AUTOSAR XML (schema 4-2-2)
package /LKAS_pkg/LKAS_swc
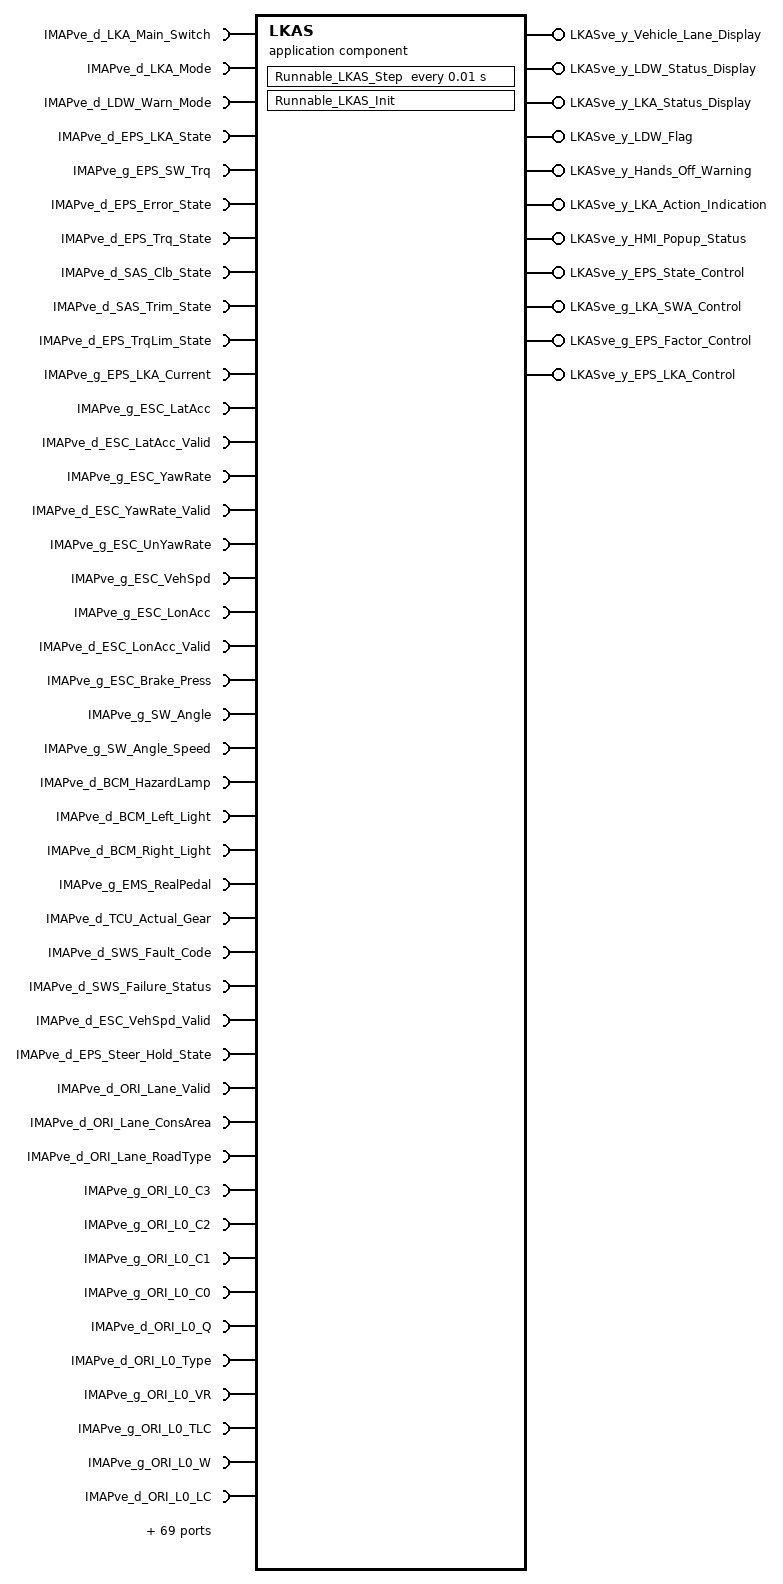
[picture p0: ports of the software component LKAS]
  application sw component type LKAS
    125 x require port:
      IMAPve_d_LKA_Main_Switch: nonqueued-receiver-com-spec{data-element=IMAPve_d_LKA_Main_Switch, init-value=0}, required-interface=IMAPve_d_LKA_Main_Switch
      IMAPve_d_LKA_Mode: nonqueued-receiver-com-spec{data-element=IMAPve_d_LKA_Mode, init-value=0}, required-interface=IMAPve_d_LKA_Mode
      IMAPve_d_LDW_Warn_Mode: nonqueued-receiver-com-spec{data-element=IMAPve_d_LDW_Warn_Mode, init-value=0}, required-interface=IMAPve_d_LDW_Warn_Mode
      IMAPve_d_EPS_LKA_State: nonqueued-receiver-com-spec{data-element=IMAPve_d_EPS_LKA_State, init-value=0}, required-interface=IMAPve_d_EPS_LKA_State
      IMAPve_g_EPS_SW_Trq: nonqueued-receiver-com-spec{data-element=IMAPve_g_EPS_SW_Trq, init-value=0}, required-interface=IMAPve_g_EPS_SW_Trq
      IMAPve_d_EPS_Error_State: nonqueued-receiver-com-spec{data-element=IMAPve_d_EPS_Error_State, init-value=0}, required-interface=IMAPve_d_EPS_Error_State
      IMAPve_d_EPS_Trq_State: nonqueued-receiver-com-spec{data-element=IMAPve_d_EPS_Trq_State, init-value=0}, required-interface=IMAPve_d_EPS_Trq_State
      IMAPve_d_SAS_Clb_State: nonqueued-receiver-com-spec{data-element=IMAPve_d_SAS_Clb_State, init-value=0}, required-interface=IMAPve_d_SAS_Clb_State
      IMAPve_d_SAS_Trim_State: nonqueued-receiver-com-spec{data-element=IMAPve_d_SAS_Trim_State, init-value=0}, required-interface=IMAPve_d_SAS_Trim_State
      IMAPve_d_EPS_TrqLim_State: nonqueued-receiver-com-spec{data-element=IMAPve_d_EPS_TrqLim_State, init-value=0}, required-interface=IMAPve_d_EPS_TrqLim_State
      IMAPve_g_EPS_LKA_Current: nonqueued-receiver-com-spec{data-element=IMAPve_g_EPS_LKA_Current, init-value=0}, required-interface=IMAPve_g_EPS_LKA_Current
      IMAPve_g_ESC_LatAcc: nonqueued-receiver-com-spec{data-element=IMAPve_g_ESC_LatAcc, init-value=0}, required-interface=IMAPve_g_ESC_LatAcc
      IMAPve_d_ESC_LatAcc_Valid: nonqueued-receiver-com-spec{data-element=IMAPve_d_ESC_LatAcc_Valid, init-value=0}, required-interface=IMAPve_d_ESC_LatAcc_Valid
      IMAPve_g_ESC_YawRate: nonqueued-receiver-com-spec{data-element=IMAPve_g_ESC_YawRate, init-value=0}, required-interface=IMAPve_g_ESC_YawRate
      IMAPve_d_ESC_YawRate_Valid: nonqueued-receiver-com-spec{data-element=IMAPve_d_ESC_YawRate_Valid, init-value=0}, required-interface=IMAPve_d_ESC_YawRate_Valid
      IMAPve_g_ESC_UnYawRate: nonqueued-receiver-com-spec{data-element=IMAPve_g_ESC_UnYawRate, init-value=0}, required-interface=IMAPve_g_ESC_UnYawRate
      IMAPve_g_ESC_VehSpd: nonqueued-receiver-com-spec{data-element=IMAPve_g_ESC_VehSpd, init-value=0}, required-interface=IMAPve_g_ESC_VehSpd
      IMAPve_g_ESC_LonAcc: nonqueued-receiver-com-spec{data-element=IMAPve_g_ESC_LonAcc, init-value=0}, required-interface=IMAPve_g_ESC_LonAcc
      IMAPve_d_ESC_LonAcc_Valid: nonqueued-receiver-com-spec{data-element=IMAPve_d_ESC_LonAcc_Valid, init-value=0}, required-interface=IMAPve_d_ESC_LonAcc_Valid
      IMAPve_g_ESC_Brake_Press: nonqueued-receiver-com-spec{data-element=IMAPve_g_ESC_Brake_Press, init-value=0}, required-interface=IMAPve_g_ESC_Brake_Press
      IMAPve_g_SW_Angle: nonqueued-receiver-com-spec{data-element=IMAPve_g_SW_Angle, init-value=0}, required-interface=IMAPve_g_SW_Angle
      IMAPve_g_SW_Angle_Speed: nonqueued-receiver-com-spec{data-element=IMAPve_g_SW_Angle_Speed, init-value=0}, required-interface=IMAPve_g_SW_Angle_Speed
      IMAPve_d_BCM_HazardLamp: nonqueued-receiver-com-spec{data-element=IMAPve_d_BCM_HazardLamp, init-value=0}, required-interface=IMAPve_d_BCM_HazardLamp
      IMAPve_d_BCM_Left_Light: nonqueued-receiver-com-spec{data-element=IMAPve_d_BCM_Left_Light, init-value=0}, required-interface=IMAPve_d_BCM_Left_Light
      IMAPve_d_BCM_Right_Light: nonqueued-receiver-com-spec{data-element=IMAPve_d_BCM_Right_Light, init-value=0}, required-interface=IMAPve_d_BCM_Right_Light
      IMAPve_g_EMS_RealPedal: nonqueued-receiver-com-spec{data-element=IMAPve_g_EMS_RealPedal, init-value=0}, required-interface=IMAPve_g_EMS_RealPedal
      IMAPve_d_TCU_Actual_Gear: nonqueued-receiver-com-spec{data-element=IMAPve_d_TCU_Actual_Gear, init-value=0}, required-interface=IMAPve_d_TCU_Actual_Gear
      IMAPve_d_SWS_Fault_Code: nonqueued-receiver-com-spec{data-element=IMAPve_d_SWS_Fault_Code, init-value=0}, required-interface=IMAPve_d_SWS_Fault_Code
      IMAPve_d_SWS_Failure_Status: nonqueued-receiver-com-spec{data-element=IMAPve_d_SWS_Failure_Status, init-value=0}, required-interface=IMAPve_d_SWS_Failure_Status
      IMAPve_d_ESC_VehSpd_Valid: nonqueued-receiver-com-spec{data-element=IMAPve_d_ESC_VehSpd_Valid, init-value=0}, required-interface=IMAPve_d_ESC_VehSpd_Valid
      IMAPve_d_EPS_Steer_Hold_State: nonqueued-receiver-com-spec{data-element=IMAPve_d_EPS_Steer_Hold_State, init-value=0}, required-interface=IMAPve_d_EPS_Steer_Hold_State
      IMAPve_d_ORI_Lane_Valid: nonqueued-receiver-com-spec{data-element=IMAPve_d_ORI_Lane_Valid, init-value=0}, required-interface=IMAPve_d_ORI_Lane_Valid
      IMAPve_d_ORI_Lane_ConsArea: nonqueued-receiver-com-spec{data-element=IMAPve_d_ORI_Lane_ConsArea, init-value=0}, required-interface=IMAPve_d_ORI_Lane_ConsArea
      IMAPve_d_ORI_Lane_RoadType: nonqueued-receiver-com-spec{data-element=IMAPve_d_ORI_Lane_RoadType, init-value=0}, required-interface=IMAPve_d_ORI_Lane_RoadType
      IMAPve_g_ORI_L0_C3: nonqueued-receiver-com-spec{data-element=IMAPve_g_ORI_L0_C3, init-value=0}, required-interface=IMAPve_g_ORI_L0_C3
      IMAPve_g_ORI_L0_C2: nonqueued-receiver-com-spec{data-element=IMAPve_g_ORI_L0_C2, init-value=0}, required-interface=IMAPve_g_ORI_L0_C2
      IMAPve_g_ORI_L0_C1: nonqueued-receiver-com-spec{data-element=IMAPve_g_ORI_L0_C1, init-value=0}, required-interface=IMAPve_g_ORI_L0_C1
      IMAPve_g_ORI_L0_C0: nonqueued-receiver-com-spec{data-element=IMAPve_g_ORI_L0_C0, init-value=0}, required-interface=IMAPve_g_ORI_L0_C0
      IMAPve_d_ORI_L0_Q: nonqueued-receiver-com-spec{data-element=IMAPve_d_ORI_L0_Q, init-value=0}, required-interface=IMAPve_d_ORI_L0_Q
      IMAPve_d_ORI_L0_Type: nonqueued-receiver-com-spec{data-element=IMAPve_d_ORI_L0_Type, init-value=0}, required-interface=IMAPve_d_ORI_L0_Type
      IMAPve_g_ORI_L0_VR: nonqueued-receiver-com-spec{data-element=IMAPve_g_ORI_L0_VR, init-value=0}, required-interface=IMAPve_g_ORI_L0_VR
      IMAPve_g_ORI_L0_TLC: nonqueued-receiver-com-spec{data-element=IMAPve_g_ORI_L0_TLC, init-value=0}, required-interface=IMAPve_g_ORI_L0_TLC
      IMAPve_g_ORI_L0_W: nonqueued-receiver-com-spec{data-element=IMAPve_g_ORI_L0_W, init-value=0}, required-interface=IMAPve_g_ORI_L0_W
      IMAPve_d_ORI_L0_LC: nonqueued-receiver-com-spec{data-element=IMAPve_d_ORI_L0_LC, init-value=0}, required-interface=IMAPve_d_ORI_L0_LC
      IMAPve_g_ORI_L1_C3: nonqueued-receiver-com-spec{data-element=IMAPve_g_ORI_L1_C3, init-value=0}, required-interface=IMAPve_g_ORI_L1_C3
      IMAPve_g_ORI_L1_C2: nonqueued-receiver-com-spec{data-element=IMAPve_g_ORI_L1_C2, init-value=0}, required-interface=IMAPve_g_ORI_L1_C2
      IMAPve_g_ORI_L1_C1: nonqueued-receiver-com-spec{data-element=IMAPve_g_ORI_L1_C1, init-value=0}, required-interface=IMAPve_g_ORI_L1_C1
      IMAPve_g_ORI_L1_C0: nonqueued-receiver-com-spec{data-element=IMAPve_g_ORI_L1_C0, init-value=0}, required-interface=IMAPve_g_ORI_L1_C0
      IMAPve_d_ORI_L1_Q: nonqueued-receiver-com-spec{data-element=IMAPve_d_ORI_L1_Q, init-value=0}, required-interface=IMAPve_d_ORI_L1_Q
      IMAPve_d_ORI_L1_Type: nonqueued-receiver-com-spec{data-element=IMAPve_d_ORI_L1_Type, init-value=0}, required-interface=IMAPve_d_ORI_L1_Type
      IMAPve_g_ORI_L1_VR: nonqueued-receiver-com-spec{data-element=IMAPve_g_ORI_L1_VR, init-value=0}, required-interface=IMAPve_g_ORI_L1_VR
      IMAPve_g_ORI_L1_TLC: nonqueued-receiver-com-spec{data-element=IMAPve_g_ORI_L1_TLC, init-value=0}, required-interface=IMAPve_g_ORI_L1_TLC
      IMAPve_g_ORI_L1_W: nonqueued-receiver-com-spec{data-element=IMAPve_g_ORI_L1_W, init-value=0}, required-interface=IMAPve_g_ORI_L1_W
      IMAPve_d_ORI_L1_LC: nonqueued-receiver-com-spec{data-element=IMAPve_d_ORI_L1_LC, init-value=0}, required-interface=IMAPve_d_ORI_L1_LC
      IMAPve_g_ORI_R0_C3: nonqueued-receiver-com-spec{data-element=IMAPve_g_ORI_R0_C3, init-value=0}, required-interface=IMAPve_g_ORI_R0_C3
      IMAPve_g_ORI_R0_C2: nonqueued-receiver-com-spec{data-element=IMAPve_g_ORI_R0_C2, init-value=0}, required-interface=IMAPve_g_ORI_R0_C2
      IMAPve_g_ORI_R0_C1: nonqueued-receiver-com-spec{data-element=IMAPve_g_ORI_R0_C1, init-value=0}, required-interface=IMAPve_g_ORI_R0_C1
      IMAPve_g_ORI_R0_C0: nonqueued-receiver-com-spec{data-element=IMAPve_g_ORI_R0_C0, init-value=0}, required-interface=IMAPve_g_ORI_R0_C0
      IMAPve_d_ORI_R0_Q: nonqueued-receiver-com-spec{data-element=IMAPve_d_ORI_R0_Q, init-value=0}, required-interface=IMAPve_d_ORI_R0_Q
      IMAPve_d_ORI_R0_LT: nonqueued-receiver-com-spec{data-element=IMAPve_d_ORI_R0_LT, init-value=0}, required-interface=IMAPve_d_ORI_R0_LT
      IMAPve_g_ORI_R0_VR: nonqueued-receiver-com-spec{data-element=IMAPve_g_ORI_R0_VR, init-value=0}, required-interface=IMAPve_g_ORI_R0_VR
      IMAPve_g_ORI_R0_TLC: nonqueued-receiver-com-spec{data-element=IMAPve_g_ORI_R0_TLC, init-value=0}, required-interface=IMAPve_g_ORI_R0_TLC
      IMAPve_g_ORI_R0_W: nonqueued-receiver-com-spec{data-element=IMAPve_g_ORI_R0_W, init-value=0}, required-interface=IMAPve_g_ORI_R0_W
      IMAPve_d_ORI_R0_LC: nonqueued-receiver-com-spec{data-element=IMAPve_d_ORI_R0_LC, init-value=0}, required-interface=IMAPve_d_ORI_R0_LC
      IMAPve_g_ORI_R1_C3: nonqueued-receiver-com-spec{data-element=IMAPve_g_ORI_R1_C3, init-value=0}, required-interface=IMAPve_g_ORI_R1_C3
      IMAPve_g_ORI_R1_C2: nonqueued-receiver-com-spec{data-element=IMAPve_g_ORI_R1_C2, init-value=0}, required-interface=IMAPve_g_ORI_R1_C2
      IMAPve_g_ORI_R1_C1: nonqueued-receiver-com-spec{data-element=IMAPve_g_ORI_R1_C1, init-value=0}, required-interface=IMAPve_g_ORI_R1_C1
      IMAPve_g_ORI_R1_C0: nonqueued-receiver-com-spec{data-element=IMAPve_g_ORI_R1_C0, init-value=0}, required-interface=IMAPve_g_ORI_R1_C0
      IMAPve_d_ORI_R1_Q: nonqueued-receiver-com-spec{data-element=IMAPve_d_ORI_R1_Q, init-value=0}, required-interface=IMAPve_d_ORI_R1_Q
      IMAPve_d_ORI_R1_LT: nonqueued-receiver-com-spec{data-element=IMAPve_d_ORI_R1_LT, init-value=0}, required-interface=IMAPve_d_ORI_R1_LT
      IMAPve_g_ORI_R1_VR: nonqueued-receiver-com-spec{data-element=IMAPve_g_ORI_R1_VR, init-value=0}, required-interface=IMAPve_g_ORI_R1_VR
      IMAPve_g_ORI_R1_TLC: nonqueued-receiver-com-spec{data-element=IMAPve_g_ORI_R1_TLC, init-value=0}, required-interface=IMAPve_g_ORI_R1_TLC
      IMAPve_g_ORI_R1_W: nonqueued-receiver-com-spec{data-element=IMAPve_g_ORI_R1_W, init-value=0}, required-interface=IMAPve_g_ORI_R1_W
      IMAPve_d_ORI_R1_LC: nonqueued-receiver-com-spec{data-element=IMAPve_d_ORI_R1_LC, init-value=0}, required-interface=IMAPve_d_ORI_R1_LC
      IMAPve_d_Sensor_Status: nonqueued-receiver-com-spec{data-element=IMAPve_d_Sensor_Status, init-value=0}, required-interface=IMAPve_d_Sensor_Status
      IMAPve_d_Fusion_Status: nonqueued-receiver-com-spec{data-element=IMAPve_d_Fusion_Status, init-value=0}, required-interface=IMAPve_d_Fusion_Status
      IMAPve_d_Lane_Valid: nonqueued-receiver-com-spec{data-element=IMAPve_d_Lane_Valid, init-value=0}, required-interface=IMAPve_d_Lane_Valid
      IMAPve_d_Road_Type: nonqueued-receiver-com-spec{data-element=IMAPve_d_Road_Type, init-value=0}, required-interface=IMAPve_d_Road_Type
      IMAPve_d_ConsArea: nonqueued-receiver-com-spec{data-element=IMAPve_d_ConsArea, init-value=0}, required-interface=IMAPve_d_ConsArea
      IMAPve_g_L0_C{0..3}: nonqueued-receiver-com-spec{data-element=IMAPve_g_L0_C{0..3}, init-value=0}, required-interface=IMAPve_g_L0_C{0..3}
      IMAPve_g_L0_VR: nonqueued-receiver-com-spec{data-element=IMAPve_g_L0_VR, init-value=0}, required-interface=IMAPve_g_L0_VR
      IMAPve_d_L0_Q: nonqueued-receiver-com-spec{data-element=IMAPve_d_L0_Q, init-value=0}, required-interface=IMAPve_d_L0_Q
      IMAPve_d_L0_Type: nonqueued-receiver-com-spec{data-element=IMAPve_d_L0_Type, init-value=0}, required-interface=IMAPve_d_L0_Type
      IMAPve_g_L0_Confidence: nonqueued-receiver-com-spec{data-element=IMAPve_g_L0_Confidence, init-value=0}, required-interface=IMAPve_g_L0_Confidence
      IMAPve_g_L0_W: nonqueued-receiver-com-spec{data-element=IMAPve_g_L0_W, init-value=0}, required-interface=IMAPve_g_L0_W
      IMAPve_g_L0_TLC: nonqueued-receiver-com-spec{data-element=IMAPve_g_L0_TLC, init-value=0}, required-interface=IMAPve_g_L0_TLC
      IMAPve_d_L0_LC: nonqueued-receiver-com-spec{data-element=IMAPve_d_L0_LC, init-value=0}, required-interface=IMAPve_d_L0_LC
      IMAPve_g_R0_C{0..3}: nonqueued-receiver-com-spec{data-element=IMAPve_g_R0_C{0..3}, init-value=0}, required-interface=IMAPve_g_R0_C{0..3}
      IMAPve_g_R0_VR: nonqueued-receiver-com-spec{data-element=IMAPve_g_R0_VR, init-value=0}, required-interface=IMAPve_g_R0_VR
      IMAPve_d_R0_Q: nonqueued-receiver-com-spec{data-element=IMAPve_d_R0_Q, init-value=0}, required-interface=IMAPve_d_R0_Q
      IMAPve_d_R0_Type: nonqueued-receiver-com-spec{data-element=IMAPve_d_R0_Type, init-value=0}, required-interface=IMAPve_d_R0_Type
      IMAPve_g_R0_Confidence: nonqueued-receiver-com-spec{data-element=IMAPve_g_R0_Confidence, init-value=0}, required-interface=IMAPve_g_R0_Confidence
      IMAPve_g_R0_W: nonqueued-receiver-com-spec{data-element=IMAPve_g_R0_W, init-value=0}, required-interface=IMAPve_g_R0_W
      IMAPve_g_R0_TLC: nonqueued-receiver-com-spec{data-element=IMAPve_g_R0_TLC, init-value=0}, required-interface=IMAPve_g_R0_TLC
      IMAPve_d_R0_LC: nonqueued-receiver-com-spec{data-element=IMAPve_d_R0_LC, init-value=0}, required-interface=IMAPve_d_R0_LC
      IMAPve_g_L1_C{0..3}: nonqueued-receiver-com-spec{data-element=IMAPve_g_L1_C{0..3}, init-value=0}, required-interface=IMAPve_g_L1_C{0..3}
      IMAPve_g_L1_VR: nonqueued-receiver-com-spec{data-element=IMAPve_g_L1_VR, init-value=0}, required-interface=IMAPve_g_L1_VR
      IMAPve_d_L1_Q: nonqueued-receiver-com-spec{data-element=IMAPve_d_L1_Q, init-value=0}, required-interface=IMAPve_d_L1_Q
      IMAPve_d_L1_Type: nonqueued-receiver-com-spec{data-element=IMAPve_d_L1_Type, init-value=0}, required-interface=IMAPve_d_L1_Type
      IMAPve_g_L1_Confidence: nonqueued-receiver-com-spec{data-element=IMAPve_g_L1_Confidence, init-value=0}, required-interface=IMAPve_g_L1_Confidence
      IMAPve_g_L1_W: nonqueued-receiver-com-spec{data-element=IMAPve_g_L1_W, init-value=0}, required-interface=IMAPve_g_L1_W
      IMAPve_g_L1_TLC: nonqueued-receiver-com-spec{data-element=IMAPve_g_L1_TLC, init-value=0}, required-interface=IMAPve_g_L1_TLC
      IMAPve_d_L1_LC: nonqueued-receiver-com-spec{data-element=IMAPve_d_L1_LC, init-value=0}, required-interface=IMAPve_d_L1_LC
      IMAPve_g_R1_C{0..3}: nonqueued-receiver-com-spec{data-element=IMAPve_g_R1_C{0..3}, init-value=0}, required-interface=IMAPve_g_R1_C{0..3}
      IMAPve_g_R1_VR: nonqueued-receiver-com-spec{data-element=IMAPve_g_R1_VR, init-value=0}, required-interface=IMAPve_g_R1_VR
      IMAPve_d_R1_Q: nonqueued-receiver-com-spec{data-element=IMAPve_d_R1_Q, init-value=0}, required-interface=IMAPve_d_R1_Q
      IMAPve_d_R1_Type: nonqueued-receiver-com-spec{data-element=IMAPve_d_R1_Type, init-value=0}, required-interface=IMAPve_d_R1_Type
      IMAPve_g_R1_Confidence: nonqueued-receiver-com-spec{data-element=IMAPve_g_R1_Confidence, init-value=0}, required-interface=IMAPve_g_R1_Confidence
      IMAPve_g_R1_W: nonqueued-receiver-com-spec{data-element=IMAPve_g_R1_W, init-value=0}, required-interface=IMAPve_g_R1_W
      IMAPve_g_R1_TLC: nonqueued-receiver-com-spec{data-element=IMAPve_g_R1_TLC, init-value=0}, required-interface=IMAPve_g_R1_TLC
      IMAPve_d_R1_LC: nonqueued-receiver-com-spec{data-element=IMAPve_d_R1_LC, init-value=0}, required-interface=IMAPve_d_R1_LC
      IMAPve_d_Camera_Signal_Fault: nonqueued-receiver-com-spec{data-element=IMAPve_d_Camera_Signal_Fault, init-value=0}, required-interface=IMAPve_d_Camera_Signal_Fault
      IMAPve_d_Camera_Status: nonqueued-receiver-com-spec{data-element=IMAPve_d_Camera_Status, init-value=0}, required-interface=IMAPve_d_Camera_Status
    11 x provide port:
      LKASve_y_Vehicle_Lane_Display: nonqueued-sender-com-spec{data-element=LKASve_y_Vehicle_Lane_Display, init-value=0}, provided-interface=LKASve_y_Vehicle_Lane_Display
      LKASve_y_LDW_Status_Display: nonqueued-sender-com-spec{data-element=LKASve_y_LDW_Status_Display, init-value=0}, provided-interface=LKASve_y_LDW_Status_Display
      LKASve_y_LKA_Status_Display: nonqueued-sender-com-spec{data-element=LKASve_y_LKA_Status_Display, init-value=0}, provided-interface=LKASve_y_LKA_Status_Display
      LKASve_y_LDW_Flag: nonqueued-sender-com-spec{data-element=LKASve_y_LDW_Flag, init-value=0}, provided-interface=LKASve_y_LDW_Flag
      LKASve_y_Hands_Off_Warning: nonqueued-sender-com-spec{data-element=LKASve_y_Hands_Off_Warning, init-value=0}, provided-interface=LKASve_y_Hands_Off_Warning
      LKASve_y_LKA_Action_Indication: nonqueued-sender-com-spec{data-element=LKASve_y_LKA_Action_Indication, init-value=0}, provided-interface=LKASve_y_LKA_Action_Indication
      LKASve_y_HMI_Popup_Status: nonqueued-sender-com-spec{data-element=LKASve_y_HMI_Popup_Status, init-value=0}, provided-interface=LKASve_y_HMI_Popup_Status
      LKASve_y_EPS_State_Control: nonqueued-sender-com-spec{data-element=LKASve_y_EPS_State_Control, init-value=0}, provided-interface=LKASve_y_EPS_State_Control
      LKASve_g_LKA_SWA_Control: nonqueued-sender-com-spec{data-element=LKASve_g_LKA_SWA_Control, init-value=0}, provided-interface=LKASve_g_LKA_SWA_Control
      LKASve_g_EPS_Factor_Control: nonqueued-sender-com-spec{data-element=LKASve_g_EPS_Factor_Control, init-value=0}, provided-interface=LKASve_g_EPS_Factor_Control
      LKASve_y_EPS_LKA_Control: nonqueued-sender-com-spec{data-element=LKASve_y_EPS_LKA_Control, init-value=0}, provided-interface=LKASve_y_EPS_LKA_Control
    behavior LKAS: handle-termination-and-restart=NO-SUPPORT
      constant-memorys:
        88 x parameter data prototype, all with category=VALUE, sw-calibration-access=READ-WRITE, type=Float:
          LKA_CarWidth: init-value=constant-reference={short-label=LKA_CarWidth, constant=LKA_CarWidth}
          LKA_SampleTime: init-value=constant-reference={short-label=LKA_SampleTime, constant=LKA_SampleTime}
          LKA_StrRatio_C: init-value=constant-reference={short-label=LKA_StrRatio_C, constant=LKA_StrRatio_C}
          LKA_Veh2CamL_C: init-value=constant-reference={short-label=LKA_Veh2CamL_C, constant=LKA_Veh2CamL_C}
          LKA_Veh2CamW_C: init-value=constant-reference={short-label=LKA_Veh2CamW_C, constant=LKA_Veh2CamW_C}
          LKA_WhlBaseL_C: init-value=constant-reference={short-label=LKA_WhlBaseL_C, constant=LKA_WhlBaseL_C}
          LL_CompSWA_C: init-value=constant-reference={short-label=LL_CompSWA_C, constant=LL_CompSWA_C}
          LL_CrvtPrvwT_C: init-value=constant-reference={short-label=LL_CrvtPrvwT_C, constant=LL_CrvtPrvwT_C}
          LL_DesDvt_C: init-value=constant-reference={short-label=LL_DesDvt_C, constant=LL_DesDvt_C}
          LL_DvtComp_C: init-value=constant-reference={short-label=LL_DvtComp_C, constant=LL_DvtComp_C}
          LL_DvtPrvwT_C: init-value=constant-reference={short-label=LL_DvtPrvwT_C, constant=LL_DvtPrvwT_C}
          LL_DvtSpdDet_vDvtSpdMin_C: init-value=constant-reference={short-label=LL_DvtSpdDet_vDvtSpdMin_C, constant=LL_DvtSpdDet_vDvtSpdMin_C}
          LL_HdAgExT_C: init-value=constant-reference={short-label=LL_HdAgExT_C, constant=LL_HdAgExT_C}
          LL_HdAgPrvwT_C: init-value=constant-reference={short-label=LL_HdAgPrvwT_C, constant=LL_HdAgPrvwT_C}
          LL_LAccMax_C: init-value=constant-reference={short-label=LL_LAccMax_C, constant=LL_LAccMax_C}
          LL_LAccRMax_C: init-value=constant-reference={short-label=LL_LAccRMax_C, constant=LL_LAccRMax_C}
          LL_LDWS_SUPPRESS_HEADING: init-value=constant-reference={short-label=LL_LDWS_SUPPRESS_HEADING, constant=LL_LDWS_SUPPRESS_HEADING}
          LL_LDW_EarliestWarnLine_C: init-value=constant-reference={short-label=LL_LDW_EarliestWarnLine_C, constant=LL_LDW_EarliestWarnLine_C}
          LL_LDW_LatestWarnLine_C: init-value=constant-reference={short-label=LL_LDW_LatestWarnLine_C, constant=LL_LDW_LatestWarnLine_C}
          LL_LFClb_TFC_DiffCtlBalance: init-value=constant-reference={short-label=LL_LFClb_TFC_DiffCtlBalance, constant=LL_LFClb_TFC_DiffCtlBalance}
          LL_LFClb_TFC_DiffCtrlMaxSWA: init-value=constant-reference={short-label=LL_LFClb_TFC_DiffCtrlMaxSWA, constant=LL_LFClb_TFC_DiffCtrlMaxSWA}
          LL_LFClb_TFC_DiffCtrlRatio: init-value=constant-reference={short-label=LL_LFClb_TFC_DiffCtrlRatio, constant=LL_LFClb_TFC_DiffCtrlRatio}
          LL_LFClb_TFC_FfCtlRatio_C: init-value=constant-reference={short-label=LL_LFClb_TFC_FfCtlRatio_C, constant=LL_LFClb_TFC_FfCtlRatio_C}
          LL_LFClb_TFC_facmGainLutGain1_C: init-value=constant-reference={short-label=LL_LFClb_TFC_facmGainLutGain1_C, constant=LL_LFClb_TFC_facmGainLutGain1_C}
          LL_LFClb_TFC_facmGainLutGain2_C: init-value=constant-reference={short-label=LL_LFClb_TFC_facmGainLutGain2_C, constant=LL_LFClb_TFC_facmGainLutGain2_C}
          LL_LFClb_TFC_facmIntegRatio: init-value=constant-reference={short-label=LL_LFClb_TFC_facmIntegRatio, constant=LL_LFClb_TFC_facmIntegRatio}
          LL_LFClb_TFC_facmKlat_C: init-value=constant-reference={short-label=LL_LFClb_TFC_facmKlat_C, constant=LL_LFClb_TFC_facmKlat_C}
          LL_LFClb_TFC_phiIntegCtlMaxSWA_C: init-value=constant-reference={short-label=LL_LFClb_TFC_phiIntegCtlMaxSWA_C, constant=LL_LFClb_TFC_phiIntegCtlMaxSWA_C}
          LL_LFClb_TFC_tiKlatPrvwT_C: init-value=constant-reference={short-label=LL_LFClb_TFC_tiKlatPrvwT_C, constant=LL_LFClb_TFC_tiKlatPrvwT_C}
          LL_LFClb_TFC_vGainLutVehSpdLwr_C: init-value=constant-reference={short-label=LL_LFClb_TFC_vGainLutVehSpdLwr_C, constant=LL_LFClb_TFC_vGainLutVehSpdLwr_C}
          LL_LFClb_TFC_vGainLutVehSpdUpr_C: init-value=constant-reference={short-label=LL_LFClb_TFC_vGainLutVehSpdUpr_C, constant=LL_LFClb_TFC_vGainLutVehSpdUpr_C}
          LL_LKAExPrcs_ExitC0Dvt: init-value=constant-reference={short-label=LL_LKAExPrcs_ExitC0Dvt, constant=LL_LKAExPrcs_ExitC0Dvt}
          LL_LKAExPrcs_ExitC0Swt: init-value=constant-reference={short-label=LL_LKAExPrcs_ExitC0Swt, constant=LL_LKAExPrcs_ExitC0Swt}
          LL_LKAExPrcs_tiExitTime{1..3}: init-value=constant-reference={short-label=LL_LKAExPrcs_tiExitTime{1..3}, constant=LL_LKAExPrcs_tiExitTime{1..3}}
          LL_LKASWASyn_M{0..2}: init-value=constant-reference={short-label=LL_LKASWASyn_M{0..2}, constant=LL_LKASWASyn_M{0..2}}
          LL_LKASWASyn_M3K: init-value=constant-reference={short-label=LL_LKASWASyn_M3K, constant=LL_LKASWASyn_M3K}
          LL_LKASWASyn_SWAaddMax: init-value=constant-reference={short-label=LL_LKASWASyn_SWAaddMax, constant=LL_LKASWASyn_SWAaddMax}
          LL_LKASWASyn_T2: init-value=constant-reference={short-label=LL_LKASWASyn_T2, constant=LL_LKASWASyn_T2}
          LL_LKASWASyn_TrqMax: init-value=constant-reference={short-label=LL_LKASWASyn_TrqMax, constant=LL_LKASWASyn_TrqMax}
          LL_LKASWASyn_TrqSwaAddSwt: init-value=constant-reference={short-label=LL_LKASWASyn_TrqSwaAddSwt, constant=LL_LKASWASyn_TrqSwaAddSwt}
          LL_LKASWASyn_TrqSwaRateDiff: init-value=constant-reference={short-label=LL_LKASWASyn_TrqSwaRateDiff, constant=LL_LKASWASyn_TrqSwaRateDiff}
          LL_LKASWASyn_tiTrqSwaRtTime: init-value=constant-reference={short-label=LL_LKASWASyn_tiTrqSwaRtTime, constant=LL_LKASWASyn_tiTrqSwaRtTime}
          LL_LKASWASyn_tiTrqSwaTime: init-value=constant-reference={short-label=LL_LKASWASyn_tiTrqSwaTime, constant=LL_LKASWASyn_tiTrqSwaTime}
          LL_LKAS_OUT_OF_CONTROL_LAT_VEL: init-value=constant-reference={short-label=LL_LKAS_OUT_OF_CONTROL_LAT_VEL, constant=LL_LKAS_OUT_OF_CONTROL_LAT_VEL}
          LL_LKAS_OUT_OF_CONTROL_TTLC: init-value=constant-reference={short-label=LL_LKAS_OUT_OF_CONTROL_TTLC, constant=LL_LKAS_OUT_OF_CONTROL_TTLC}
          LL_LKA_EarliestWarnLine_C: init-value=constant-reference={short-label=LL_LKA_EarliestWarnLine_C, constant=LL_LKA_EarliestWarnLine_C}
          LL_LKA_LatestWarnLine_C: init-value=constant-reference={short-label=LL_LKA_LatestWarnLine_C, constant=LL_LKA_LatestWarnLine_C}
          LL_LSpdCompT_C: init-value=constant-reference={short-label=LL_LSpdCompT_C, constant=LL_LSpdCompT_C}
          LL_MAX_DELAY_EPSSTAR_TIME: init-value=constant-reference={short-label=LL_MAX_DELAY_EPSSTAR_TIME, constant=LL_MAX_DELAY_EPSSTAR_TIME}
          LL_MAX_DRIVER_TORQUE_DISABLE: init-value=constant-reference={short-label=LL_MAX_DRIVER_TORQUE_DISABLE, constant=LL_MAX_DRIVER_TORQUE_DISABLE}
          LL_MAX_DRIVER_TORQUE_ENABLE: init-value=constant-reference={short-label=LL_MAX_DRIVER_TORQUE_ENABLE, constant=LL_MAX_DRIVER_TORQUE_ENABLE}
          LL_MAX_LANE_WIDTH_DISABLE: init-value=constant-reference={short-label=LL_MAX_LANE_WIDTH_DISABLE, constant=LL_MAX_LANE_WIDTH_DISABLE}
          LL_MAX_LANE_WIDTH_ENABLE: init-value=constant-reference={short-label=LL_MAX_LANE_WIDTH_ENABLE, constant=LL_MAX_LANE_WIDTH_ENABLE}
          LL_MAX_LAT_ACC_DISABLE: init-value=constant-reference={short-label=LL_MAX_LAT_ACC_DISABLE, constant=LL_MAX_LAT_ACC_DISABLE}
          LL_MAX_LAT_ACC_ENABLE: init-value=constant-reference={short-label=LL_MAX_LAT_ACC_ENABLE, constant=LL_MAX_LAT_ACC_ENABLE}
          LL_MAX_LDWS_SPEED_DISABLE: init-value=constant-reference={short-label=LL_MAX_LDWS_SPEED_DISABLE, constant=LL_MAX_LDWS_SPEED_DISABLE}
          LL_MAX_LDWS_SPEED_ENABLE: init-value=constant-reference={short-label=LL_MAX_LDWS_SPEED_ENABLE, constant=LL_MAX_LDWS_SPEED_ENABLE}
          LL_MAX_LKAS_SPEED_DISABLE: init-value=constant-reference={short-label=LL_MAX_LKAS_SPEED_DISABLE, constant=LL_MAX_LKAS_SPEED_DISABLE}
          LL_MAX_LKAS_SPEED_ENABLE: init-value=constant-reference={short-label=LL_MAX_LKAS_SPEED_ENABLE, constant=LL_MAX_LKAS_SPEED_ENABLE}
          LL_MAX_LONG_ACC_DISABLE: init-value=constant-reference={short-label=LL_MAX_LONG_ACC_DISABLE, constant=LL_MAX_LONG_ACC_DISABLE}
          LL_MAX_LONG_ACC_ENABLE: init-value=constant-reference={short-label=LL_MAX_LONG_ACC_ENABLE, constant=LL_MAX_LONG_ACC_ENABLE}
          LL_MAX_LONG_DECEL_DISABLE: init-value=constant-reference={short-label=LL_MAX_LONG_DECEL_DISABLE, constant=LL_MAX_LONG_DECEL_DISABLE}
          LL_MAX_LONG_DECEL_ENABLE: init-value=constant-reference={short-label=LL_MAX_LONG_DECEL_ENABLE, constant=LL_MAX_LONG_DECEL_ENABLE}
          LL_MAX_STEER_ANGLE_DISABLE: init-value=constant-reference={short-label=LL_MAX_STEER_ANGLE_DISABLE, constant=LL_MAX_STEER_ANGLE_DISABLE}
          LL_MAX_STEER_ANGLE_ENABLE: init-value=constant-reference={short-label=LL_MAX_STEER_ANGLE_ENABLE, constant=LL_MAX_STEER_ANGLE_ENABLE}
          LL_MAX_STEER_SPEED_DISABLE: init-value=constant-reference={short-label=LL_MAX_STEER_SPEED_DISABLE, constant=LL_MAX_STEER_SPEED_DISABLE}
          LL_MAX_STEER_SPEED_ENABLE: init-value=constant-reference={short-label=LL_MAX_STEER_SPEED_ENABLE, constant=LL_MAX_STEER_SPEED_ENABLE}
          LL_MAX_SYSTEM_CURVATURE_DISABLE: init-value=constant-reference={short-label=LL_MAX_SYSTEM_CURVATURE_DISABLE, constant=LL_MAX_SYSTEM_CURVATURE_DISABLE}
          LL_MAX_SYSTEM_CURVATURE_ENABLE: init-value=constant-reference={short-label=LL_MAX_SYSTEM_CURVATURE_ENABLE, constant=LL_MAX_SYSTEM_CURVATURE_ENABLE}
          LL_MIN_LANE_WIDTH_DISABLE: init-value=constant-reference={short-label=LL_MIN_LANE_WIDTH_DISABLE, constant=LL_MIN_LANE_WIDTH_DISABLE}
          LL_MIN_LANE_WIDTH_ENABLE: init-value=constant-reference={short-label=LL_MIN_LANE_WIDTH_ENABLE, constant=LL_MIN_LANE_WIDTH_ENABLE}
          LL_MIN_LKAS_SPEED_DISABLE: init-value=constant-reference={short-label=LL_MIN_LKAS_SPEED_DISABLE, constant=LL_MIN_LKAS_SPEED_DISABLE}
          LL_MIN_LKAS_SPEED_ENABLE: init-value=constant-reference={short-label=LL_MIN_LKAS_SPEED_ENABLE, constant=LL_MIN_LKAS_SPEED_ENABLE}
          LL_Max_LDWS_Warning_Time: init-value=constant-reference={short-label=LL_Max_LDWS_Warning_Time, constant=LL_Max_LDWS_Warning_Time}
          LL_NomTAhd_C: init-value=constant-reference={short-label=LL_NomTAhd_C, constant=LL_NomTAhd_C}
          LL_ThresDet_lDvtThresLwrLDW: init-value=constant-reference={short-label=LL_ThresDet_lDvtThresLwrLDW, constant=LL_ThresDet_lDvtThresLwrLDW}
          LL_ThresDet_lDvtThresLwrLKA: init-value=constant-reference={short-label=LL_ThresDet_lDvtThresLwrLKA, constant=LL_ThresDet_lDvtThresLwrLKA}
          LL_ThresDet_lDvtThresUprLDW: init-value=constant-reference={short-label=LL_ThresDet_lDvtThresUprLDW, constant=LL_ThresDet_lDvtThresUprLDW}
          LL_ThresDet_lDvtThresUprLKA: init-value=constant-reference={short-label=LL_ThresDet_lDvtThresUprLKA, constant=LL_ThresDet_lDvtThresUprLKA}
          LL_ThresDet_tiTTLCThresLDW: init-value=constant-reference={short-label=LL_ThresDet_tiTTLCThresLDW, constant=LL_ThresDet_tiTTLCThresLDW}
          LL_ThresDet_tiTTLCThresLKA: init-value=constant-reference={short-label=LL_ThresDet_tiTTLCThresLKA, constant=LL_ThresDet_tiTTLCThresLKA}
          LL_TkOvStChk_tiTDelTime: init-value=constant-reference={short-label=LL_TkOvStChk_tiTDelTime, constant=LL_TkOvStChk_tiTDelTime}
          LL_TkOvStChk_tiTrqChkT: init-value=constant-reference={short-label=LL_TkOvStChk_tiTrqChkT, constant=LL_TkOvStChk_tiTrqChkT}
          LL_lStpLngth_C: init-value=constant-reference={short-label=LL_lStpLngth_C, constant=LL_lStpLngth_C}
      timing event Event_LKAS_Step: start-on-event=Runnable_LKAS_Step, period=0.01
      init event Event_LKAS_Init: start-on-event=Runnable_LKAS_Init
      runnable Runnable_LKAS_Init
      runnable Runnable_LKAS_Step
        data-receive-point-by-arguments:
          125 x access:
            IN_IMAPve_d_BCM_45f6cdd3d06d39c8: accessed-variable=IMAPve_d_BCM_HazardLamp.IMAPve_d_BCM_HazardLamp
            IN_IMAPve_d_BCM_09851a84e2d82cb2: accessed-variable=IMAPve_d_BCM_Left_Light.IMAPve_d_BCM_Left_Light
            IN_IMAPve_d_BCM_98aaeba56ed71e30: accessed-variable=IMAPve_d_BCM_Right_Light.IMAPve_d_BCM_Right_Light
            IN_IMAPve_d_Cam_4e98d508cc7c5b1e: accessed-variable=IMAPve_d_Camera_Signal_Fault.IMAPve_d_Camera_Signal_Fault
            IN_IMAPve_d_Cam_77dad3ae7c90c097: accessed-variable=IMAPve_d_Camera_Status.IMAPve_d_Camera_Status
            IN_IMAPve_d_Con_4cb5f48114024151: accessed-variable=IMAPve_d_ConsArea.IMAPve_d_ConsArea
            IN_IMAPve_d_EPS_7e51b6f0fd2cd2fb: accessed-variable=IMAPve_d_EPS_Error_State.IMAPve_d_EPS_Error_State
            IN_IMAPve_d_EPS_4980106fb16cb52d: accessed-variable=IMAPve_d_EPS_LKA_State.IMAPve_d_EPS_LKA_State
            IN_IMAPve_d_EPS_30ad37aefbe13933: accessed-variable=IMAPve_d_EPS_Steer_Hold_State.IMAPve_d_EPS_Steer_Hold_State
            IN_IMAPve_d_EPS_1bbe0f83fc3fe6cc: accessed-variable=IMAPve_d_EPS_TrqLim_State.IMAPve_d_EPS_TrqLim_State
            IN_IMAPve_d_EPS_1c07a06b23c988f8: accessed-variable=IMAPve_d_EPS_Trq_State.IMAPve_d_EPS_Trq_State
            IN_IMAPve_d_ESC_f69a5ccc4ec45f2e: accessed-variable=IMAPve_d_ESC_LatAcc_Valid.IMAPve_d_ESC_LatAcc_Valid
            IN_IMAPve_d_ESC_88d37f3d03340a25: accessed-variable=IMAPve_d_ESC_LonAcc_Valid.IMAPve_d_ESC_LonAcc_Valid
            IN_IMAPve_d_ESC_072ac8953c5ffe86: accessed-variable=IMAPve_d_ESC_VehSpd_Valid.IMAPve_d_ESC_VehSpd_Valid
            IN_IMAPve_d_ESC_1ba450320c861872: accessed-variable=IMAPve_d_ESC_YawRate_Valid.IMAPve_d_ESC_YawRate_Valid
            IN_IMAPve_d_Fus_177c7ef9a707e6ba: accessed-variable=IMAPve_d_Fusion_Status.IMAPve_d_Fusion_Status
            IN_IMAPve_d_L0_LC_IMAPve_d_L0_LC: accessed-variable=IMAPve_d_L0_LC.IMAPve_d_L0_LC
            IN_IMAPve_d_L0_Q_IMAPve_d_L0_Q: accessed-variable=IMAPve_d_L0_Q.IMAPve_d_L0_Q
            IN_IMAPve_d_L0_2674d0194a74b2f6: accessed-variable=IMAPve_d_L0_Type.IMAPve_d_L0_Type
            IN_IMAPve_d_L1_LC_IMAPve_d_L1_LC: accessed-variable=IMAPve_d_L1_LC.IMAPve_d_L1_LC
            IN_IMAPve_d_L1_Q_IMAPve_d_L1_Q: accessed-variable=IMAPve_d_L1_Q.IMAPve_d_L1_Q
            IN_IMAPve_d_L1_b2dad4b0d07d9fd4: accessed-variable=IMAPve_d_L1_Type.IMAPve_d_L1_Type
            IN_IMAPve_d_LDW_84588828239301bc: accessed-variable=IMAPve_d_LDW_Warn_Mode.IMAPve_d_LDW_Warn_Mode
            IN_IMAPve_d_LKA_aef50e96e24c310b: accessed-variable=IMAPve_d_LKA_Main_Switch.IMAPve_d_LKA_Main_Switch
            IN_IMAPve_d_LKA_297f60c178f22f0c: accessed-variable=IMAPve_d_LKA_Mode.IMAPve_d_LKA_Mode
            IN_IMAPve_d_Lan_5d199d1ba5742b65: accessed-variable=IMAPve_d_Lane_Valid.IMAPve_d_Lane_Valid
            IN_IMAPve_d_ORI_2ba8fdc19c753035: accessed-variable=IMAPve_d_ORI_L0_LC.IMAPve_d_ORI_L0_LC
            IN_IMAPve_d_ORI_a7f239c0c3fe70d4: accessed-variable=IMAPve_d_ORI_L0_Q.IMAPve_d_ORI_L0_Q
            IN_IMAPve_d_ORI_9e8572806020b8ae: accessed-variable=IMAPve_d_ORI_L0_Type.IMAPve_d_ORI_L0_Type
            IN_IMAPve_d_ORI_818b0f8ce08edc51: accessed-variable=IMAPve_d_ORI_L1_LC.IMAPve_d_ORI_L1_LC
            IN_IMAPve_d_ORI_e1a9805b4dfa9a1d: accessed-variable=IMAPve_d_ORI_L1_Q.IMAPve_d_ORI_L1_Q
            IN_IMAPve_d_ORI_64ce1fe691dc5a40: accessed-variable=IMAPve_d_ORI_L1_Type.IMAPve_d_ORI_L1_Type
            IN_IMAPve_d_ORI_af892cd029840045: accessed-variable=IMAPve_d_ORI_Lane_ConsArea.IMAPve_d_ORI_Lane_ConsArea
            IN_IMAPve_d_ORI_54542cf1ad064c18: accessed-variable=IMAPve_d_ORI_Lane_RoadType.IMAPve_d_ORI_Lane_RoadType
            IN_IMAPve_d_ORI_09586a1b1a783ad3: accessed-variable=IMAPve_d_ORI_Lane_Valid.IMAPve_d_ORI_Lane_Valid
            IN_IMAPve_d_ORI_8bf10628b0f10ddc: accessed-variable=IMAPve_d_ORI_R0_LC.IMAPve_d_ORI_R0_LC
            IN_IMAPve_d_ORI_4733a5052ac5f8fa: accessed-variable=IMAPve_d_ORI_R0_LT.IMAPve_d_ORI_R0_LT
            IN_IMAPve_d_ORI_6a6117ba48de209f: accessed-variable=IMAPve_d_ORI_R0_Q.IMAPve_d_ORI_R0_Q
            IN_IMAPve_d_ORI_4fb72f7812e57f50: accessed-variable=IMAPve_d_ORI_R1_LC.IMAPve_d_ORI_R1_LC
            IN_IMAPve_d_ORI_fb79d34114537b98: accessed-variable=IMAPve_d_ORI_R1_LT.IMAPve_d_ORI_R1_LT
            IN_IMAPve_d_ORI_93c107e9420b597b: accessed-variable=IMAPve_d_ORI_R1_Q.IMAPve_d_ORI_R1_Q
            IN_IMAPve_d_R0_LC_IMAPve_d_R0_LC: accessed-variable=IMAPve_d_R0_LC.IMAPve_d_R0_LC
            IN_IMAPve_d_R0_Q_IMAPve_d_R0_Q: accessed-variable=IMAPve_d_R0_Q.IMAPve_d_R0_Q
            IN_IMAPve_d_R0_c2cdaf5197c59ede: accessed-variable=IMAPve_d_R0_Type.IMAPve_d_R0_Type
            IN_IMAPve_d_R1_LC_IMAPve_d_R1_LC: accessed-variable=IMAPve_d_R1_LC.IMAPve_d_R1_LC
            IN_IMAPve_d_R1_Q_IMAPve_d_R1_Q: accessed-variable=IMAPve_d_R1_Q.IMAPve_d_R1_Q
            IN_IMAPve_d_R1_af84472b20fa0199: accessed-variable=IMAPve_d_R1_Type.IMAPve_d_R1_Type
            IN_IMAPve_d_Roa_8e1fdc9ae545f712: accessed-variable=IMAPve_d_Road_Type.IMAPve_d_Road_Type
            IN_IMAPve_d_SAS_796149af675dcca4: accessed-variable=IMAPve_d_SAS_Clb_State.IMAPve_d_SAS_Clb_State
            IN_IMAPve_d_SAS_78cd967e09017e19: accessed-variable=IMAPve_d_SAS_Trim_State.IMAPve_d_SAS_Trim_State
            IN_IMAPve_d_SWS_f781b300d1ae06b4: accessed-variable=IMAPve_d_SWS_Failure_Status.IMAPve_d_SWS_Failure_Status
            IN_IMAPve_d_SWS_d1f7896f9bb440b9: accessed-variable=IMAPve_d_SWS_Fault_Code.IMAPve_d_SWS_Fault_Code
            IN_IMAPve_d_Sen_9e661b487e993ebb: accessed-variable=IMAPve_d_Sensor_Status.IMAPve_d_Sensor_Status
            IN_IMAPve_d_TCU_121f9b14064833f2: accessed-variable=IMAPve_d_TCU_Actual_Gear.IMAPve_d_TCU_Actual_Gear
            IN_IMAPve_g_EMS_a8a88ac0781dea3a: accessed-variable=IMAPve_g_EMS_RealPedal.IMAPve_g_EMS_RealPedal
            IN_IMAPve_g_EPS_9ec3610a30e42395: accessed-variable=IMAPve_g_EPS_LKA_Current.IMAPve_g_EPS_LKA_Current
            IN_IMAPve_g_EPS_ccde421a6ee0d22b: accessed-variable=IMAPve_g_EPS_SW_Trq.IMAPve_g_EPS_SW_Trq
            IN_IMAPve_g_ESC_aad78934f5f285ca: accessed-variable=IMAPve_g_ESC_Brake_Press.IMAPve_g_ESC_Brake_Press
            IN_IMAPve_g_ESC_ae271d77144840c5: accessed-variable=IMAPve_g_ESC_LatAcc.IMAPve_g_ESC_LatAcc
            IN_IMAPve_g_ESC_1aae3aea4ae0d968: accessed-variable=IMAPve_g_ESC_LonAcc.IMAPve_g_ESC_LonAcc
            IN_IMAPve_g_ESC_4a32050b53972fa6: accessed-variable=IMAPve_g_ESC_UnYawRate.IMAPve_g_ESC_UnYawRate
            IN_IMAPve_g_ESC_4bcc76b5ccd16be4: accessed-variable=IMAPve_g_ESC_VehSpd.IMAPve_g_ESC_VehSpd
            IN_IMAPve_g_ESC_71e9e33027b6e6b7: accessed-variable=IMAPve_g_ESC_YawRate.IMAPve_g_ESC_YawRate
            IN_IMAPve_g_L0_C{0..3}_IMAPve_g_L0_C{0..3}: accessed-variable=IMAPve_g_L0_C{0..3}.IMAPve_g_L0_C{0..3}
            IN_IMAPve_g_L0_4dd5759d0ba70b47: accessed-variable=IMAPve_g_L0_Confidence.IMAPve_g_L0_Confidence
            IN_IMAPve_g_L0_613e898cdbeb7b72: accessed-variable=IMAPve_g_L0_TLC.IMAPve_g_L0_TLC
            IN_IMAPve_g_L0_VR_IMAPve_g_L0_VR: accessed-variable=IMAPve_g_L0_VR.IMAPve_g_L0_VR
            IN_IMAPve_g_L0_W_IMAPve_g_L0_W: accessed-variable=IMAPve_g_L0_W.IMAPve_g_L0_W
            IN_IMAPve_g_L1_C{0..3}_IMAPve_g_L1_C{0..3}: accessed-variable=IMAPve_g_L1_C{0..3}.IMAPve_g_L1_C{0..3}
            IN_IMAPve_g_L1_6acf8111a0b360ed: accessed-variable=IMAPve_g_L1_Confidence.IMAPve_g_L1_Confidence
            IN_IMAPve_g_L1_291d824c9312676c: accessed-variable=IMAPve_g_L1_TLC.IMAPve_g_L1_TLC
            IN_IMAPve_g_L1_VR_IMAPve_g_L1_VR: accessed-variable=IMAPve_g_L1_VR.IMAPve_g_L1_VR
            IN_IMAPve_g_L1_W_IMAPve_g_L1_W: accessed-variable=IMAPve_g_L1_W.IMAPve_g_L1_W
            IN_IMAPve_g_ORI_59d0752ccd0f94f8: accessed-variable=IMAPve_g_ORI_L0_C0.IMAPve_g_ORI_L0_C0
            IN_IMAPve_g_ORI_50d617de5f40b652: accessed-variable=IMAPve_g_ORI_L0_C1.IMAPve_g_ORI_L0_C1
            IN_IMAPve_g_ORI_b39438ce2c2805b3: accessed-variable=IMAPve_g_ORI_L0_C2.IMAPve_g_ORI_L0_C2
            IN_IMAPve_g_ORI_40689a9c50e1cfe9: accessed-variable=IMAPve_g_ORI_L0_C3.IMAPve_g_ORI_L0_C3
            IN_IMAPve_g_ORI_27baf85ad6181227: accessed-variable=IMAPve_g_ORI_L0_TLC.IMAPve_g_ORI_L0_TLC
            IN_IMAPve_g_ORI_9169185bf8685912: accessed-variable=IMAPve_g_ORI_L0_VR.IMAPve_g_ORI_L0_VR
            IN_IMAPve_g_ORI_467d03855d7bfefe: accessed-variable=IMAPve_g_ORI_L0_W.IMAPve_g_ORI_L0_W
            IN_IMAPve_g_ORI_76bf2405d5217ddc: accessed-variable=IMAPve_g_ORI_L1_C0.IMAPve_g_ORI_L1_C0
            IN_IMAPve_g_ORI_aa53addc8a02bad8: accessed-variable=IMAPve_g_ORI_L1_C1.IMAPve_g_ORI_L1_C1
            IN_IMAPve_g_ORI_cf7c007df6deb902: accessed-variable=IMAPve_g_ORI_L1_C2.IMAPve_g_ORI_L1_C2
            IN_IMAPve_g_ORI_94d5449b3aa885e1: accessed-variable=IMAPve_g_ORI_L1_C3.IMAPve_g_ORI_L1_C3
            IN_IMAPve_g_ORI_bdffa10d16ba15e0: accessed-variable=IMAPve_g_ORI_L1_TLC.IMAPve_g_ORI_L1_TLC
            IN_IMAPve_g_ORI_ae4438a0a22b23b9: accessed-variable=IMAPve_g_ORI_L1_VR.IMAPve_g_ORI_L1_VR
            IN_IMAPve_g_ORI_c710d7e4ef9d260f: accessed-variable=IMAPve_g_ORI_L1_W.IMAPve_g_ORI_L1_W
            IN_IMAPve_g_ORI_5ad23543f011db9d: accessed-variable=IMAPve_g_ORI_R0_C0.IMAPve_g_ORI_R0_C0
            IN_IMAPve_g_ORI_affa96682372fc27: accessed-variable=IMAPve_g_ORI_R0_C1.IMAPve_g_ORI_R0_C1
            IN_IMAPve_g_ORI_803915d28ced4a71: accessed-variable=IMAPve_g_ORI_R0_C2.IMAPve_g_ORI_R0_C2
            IN_IMAPve_g_ORI_19358efcf4ab221e: accessed-variable=IMAPve_g_ORI_R0_C3.IMAPve_g_ORI_R0_C3
            IN_IMAPve_g_ORI_8e21ac9344de260e: accessed-variable=IMAPve_g_ORI_R0_TLC.IMAPve_g_ORI_R0_TLC
            IN_IMAPve_g_ORI_caadeefbcf760192: accessed-variable=IMAPve_g_ORI_R0_VR.IMAPve_g_ORI_R0_VR
            IN_IMAPve_g_ORI_ee757793296ad771: accessed-variable=IMAPve_g_ORI_R0_W.IMAPve_g_ORI_R0_W
            IN_IMAPve_g_ORI_b3cc20a071fc3c3b: accessed-variable=IMAPve_g_ORI_R1_C0.IMAPve_g_ORI_R1_C0
            IN_IMAPve_g_ORI_ef774cbcfcf4aaf8: accessed-variable=IMAPve_g_ORI_R1_C1.IMAPve_g_ORI_R1_C1
            IN_IMAPve_g_ORI_a4e1a3827d3ef90a: accessed-variable=IMAPve_g_ORI_R1_C2.IMAPve_g_ORI_R1_C2
            IN_IMAPve_g_ORI_71b8d286b1a728c3: accessed-variable=IMAPve_g_ORI_R1_C3.IMAPve_g_ORI_R1_C3
            IN_IMAPve_g_ORI_af19e53d36bbbb6b: accessed-variable=IMAPve_g_ORI_R1_TLC.IMAPve_g_ORI_R1_TLC
            IN_IMAPve_g_ORI_d8d822dbcb7e32b8: accessed-variable=IMAPve_g_ORI_R1_VR.IMAPve_g_ORI_R1_VR
            IN_IMAPve_g_ORI_5f34e1730075875c: accessed-variable=IMAPve_g_ORI_R1_W.IMAPve_g_ORI_R1_W
            IN_IMAPve_g_R0_C{0..3}_IMAPve_g_R0_C{0..3}: accessed-variable=IMAPve_g_R0_C{0..3}.IMAPve_g_R0_C{0..3}
            IN_IMAPve_g_R0_dcf45a2dfa1cb200: accessed-variable=IMAPve_g_R0_Confidence.IMAPve_g_R0_Confidence
            IN_IMAPve_g_R0_4a249eea954ee2f2: accessed-variable=IMAPve_g_R0_TLC.IMAPve_g_R0_TLC
            IN_IMAPve_g_R0_VR_IMAPve_g_R0_VR: accessed-variable=IMAPve_g_R0_VR.IMAPve_g_R0_VR
            IN_IMAPve_g_R0_W_IMAPve_g_R0_W: accessed-variable=IMAPve_g_R0_W.IMAPve_g_R0_W
            IN_IMAPve_g_R1_C{0..3}_IMAPve_g_R1_C{0..3}: accessed-variable=IMAPve_g_R1_C{0..3}.IMAPve_g_R1_C{0..3}
            IN_IMAPve_g_R1_0460de4d2235a211: accessed-variable=IMAPve_g_R1_Confidence.IMAPve_g_R1_Confidence
            IN_IMAPve_g_R1_e65239acddbae6b7: accessed-variable=IMAPve_g_R1_TLC.IMAPve_g_R1_TLC
            IN_IMAPve_g_R1_VR_IMAPve_g_R1_VR: accessed-variable=IMAPve_g_R1_VR.IMAPve_g_R1_VR
            IN_IMAPve_g_R1_W_IMAPve_g_R1_W: accessed-variable=IMAPve_g_R1_W.IMAPve_g_R1_W
            IN_IMAPve_g_SW_09f01be4a8e6cfb9: accessed-variable=IMAPve_g_SW_Angle.IMAPve_g_SW_Angle
            IN_IMAPve_g_SW_ab7908228801b38e: accessed-variable=IMAPve_g_SW_Angle_Speed.IMAPve_g_SW_Angle_Speed
        data-send-points:
          11 x access:
            OUT_LKASve_y_Ve_2887fe747d0aaf6b: accessed-variable=LKASve_y_Vehicle_Lane_Display.LKASve_y_Vehicle_Lane_Display
            OUT_LKASve_y_LD_c3aa57431bb07884: accessed-variable=LKASve_y_LDW_Status_Display.LKASve_y_LDW_Status_Display
            OUT_LKASve_y_LK_993706f24c9c11d9: accessed-variable=LKASve_y_LKA_Status_Display.LKASve_y_LKA_Status_Display
            OUT_LKASve_y_LD_2b70c3502d91050f: accessed-variable=LKASve_y_LDW_Flag.LKASve_y_LDW_Flag
            OUT_LKASve_y_Ha_6cfd84ca2acec963: accessed-variable=LKASve_y_Hands_Off_Warning.LKASve_y_Hands_Off_Warning
            OUT_LKASve_y_LK_5fe1f479df36e597: accessed-variable=LKASve_y_LKA_Action_Indication.LKASve_y_LKA_Action_Indication
            OUT_LKASve_y_HM_7c2e032e044df553: accessed-variable=LKASve_y_HMI_Popup_Status.LKASve_y_HMI_Popup_Status
            OUT_LKASve_y_EP_0f1e8d45e7d40df4: accessed-variable=LKASve_y_EPS_State_Control.LKASve_y_EPS_State_Control
            OUT_LKASve_g_LK_44b524232ebbfdae: accessed-variable=LKASve_g_LKA_SWA_Control.LKASve_g_LKA_SWA_Control
            OUT_LKASve_g_EP_d170ba81a0afd4ef: accessed-variable=LKASve_g_EPS_Factor_Control.LKASve_g_EPS_Factor_Control
            OUT_LKASve_y_EP_b3947e44cc394638: accessed-variable=LKASve_y_EPS_LKA_Control.LKASve_y_EPS_LKA_Control
